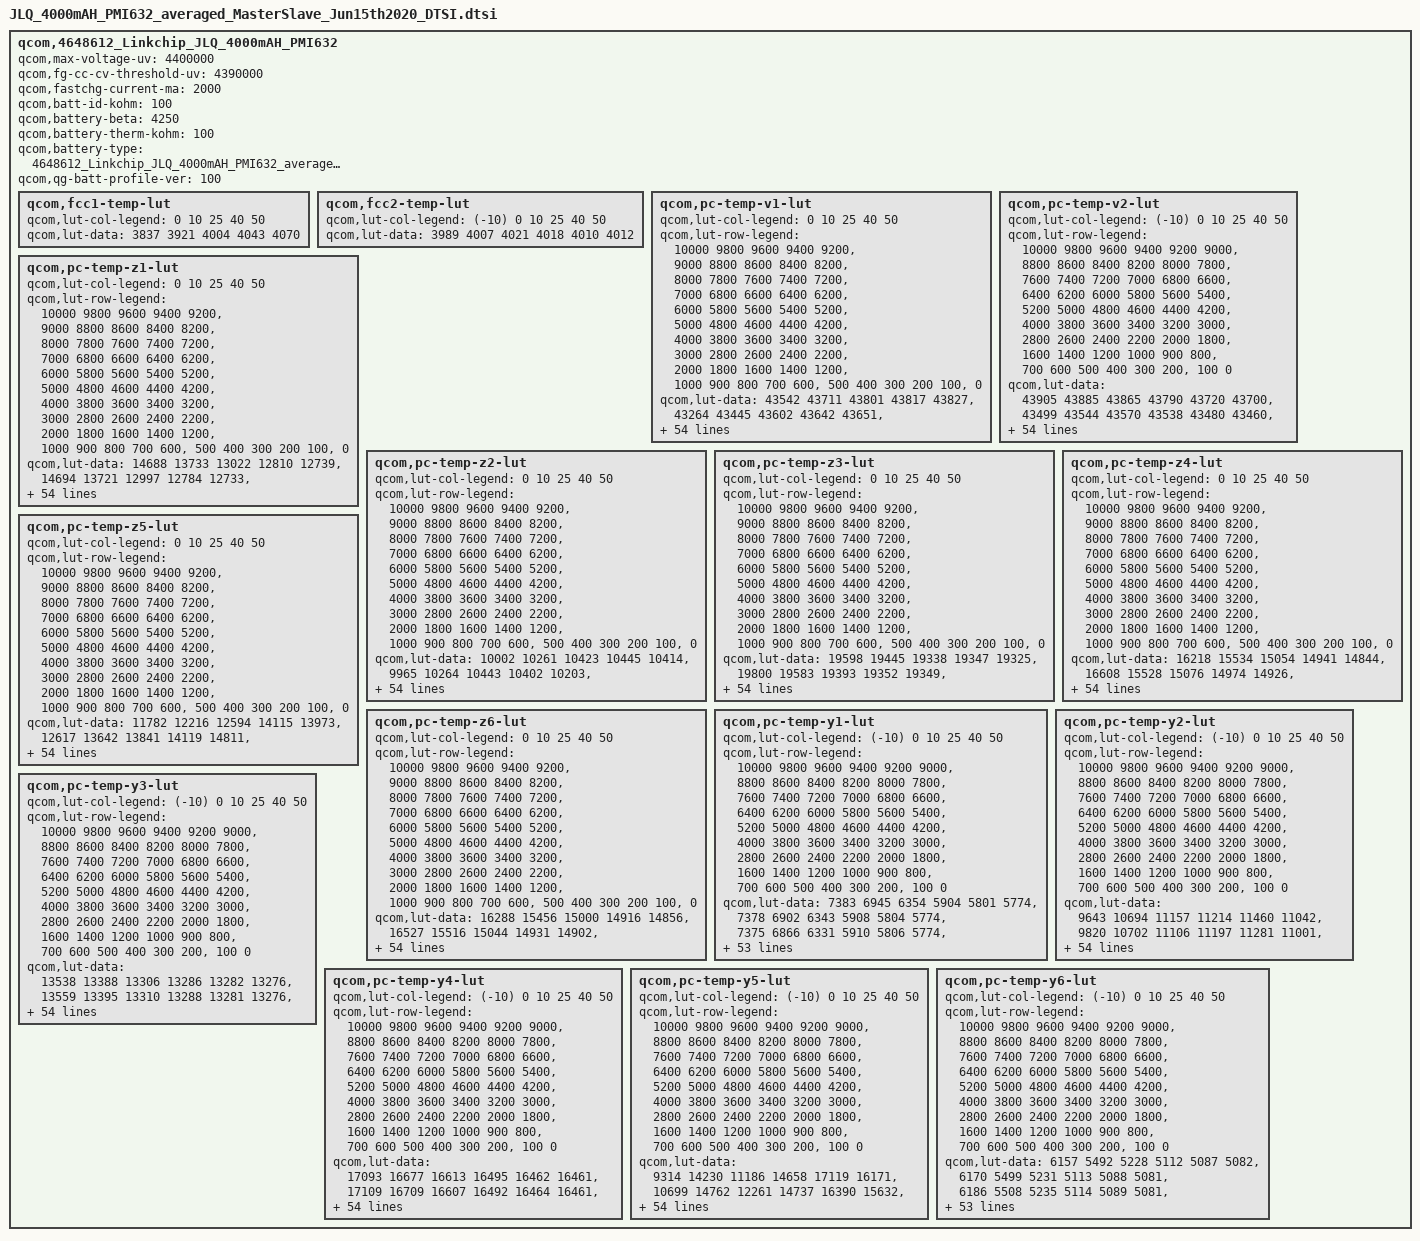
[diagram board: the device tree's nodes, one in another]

qcom,4648612_Linkchip_JLQ_4000mAH_PMI632 {
    /* 4648612_Linkchip_JLQ_4000mAH_PMI632_averaged_MasterSlave_Jun15th2020 */
    qcom,max-voltage-uv = <4400000>;
    qcom,fg-cc-cv-threshold-uv = <4390000>;
    qcom,fastchg-current-ma = <2000>;
    qcom,batt-id-kohm = <100>;
    qcom,battery-beta = <4250>;
    qcom,battery-therm-kohm = <100>;
    qcom,battery-type = "4648612_Linkchip_JLQ_4000mAH_PMI632_averaged_MasterSlave_Jun15th2020";
    qcom,qg-batt-profile-ver = <100>;

	qcom,fcc1-temp-lut {
		qcom,lut-col-legend = <0 10 25 40 50>;
		qcom,lut-data = <3837 3921 4004 4043 4070>;
	};

	qcom,fcc2-temp-lut {
		qcom,lut-col-legend = <(-10) 0 10 25 40 50>;
		qcom,lut-data = <3989 4007 4021 4018 4010 4012>;
	};

	qcom,pc-temp-v1-lut {
		qcom,lut-col-legend = <0 10 25 40 50>;
		qcom,lut-row-legend = <10000 9800 9600 9400 9200>,
			<9000 8800 8600 8400 8200>,
			<8000 7800 7600 7400 7200>,
			<7000 6800 6600 6400 6200>,
			<6000 5800 5600 5400 5200>,
			<5000 4800 4600 4400 4200>,
			<4000 3800 3600 3400 3200>,
			<3000 2800 2600 2400 2200>,
			<2000 1800 1600 1400 1200>,
			<1000 900 800 700 600>,
			<500 400 300 200 100>,
			<0>;
		qcom,lut-data = <43542 43711 43801 43817 43827>,
			<43264 43445 43602 43642 43651>,
			<43025 43195 43371 43428 43448>,
			<42799 42961 43136 43203 43229>,
			<42574 42733 42900 42970 43002>,
			<42354 42505 42663 42730 42764>,
			<42138 42278 42430 42492 42526>,
			<41925 42058 42199 42256 42289>,
			<41718 41843 41972 42023 42055>,
			<41517 41632 41748 41793 41822>,
			<41325 41428 41528 41566 41592>,
			<41130 41234 41315 41344 41367>,
			<40927 41036 41109 41127 41145>,
			<40709 40831 40906 40917 40929>,
			<40446 40607 40699 40709 40718>,
			<40099 40332 40480 40498 40510>,
			<39816 40009 40219 40283 40311>,
			<39682 39791 39957 40069 40124>,
			<39590 39687 39785 39882 39941>,
			<39496 39605 39676 39730 39767>,
			<39400 39486 39552 39575 39592>,
			<39300 39332 39323 39346 39372>,
			<39185 39162 39041 39040 39079>,
			<39056 38963 38839 38824 38849>,
			<38933 38761 38686 38708 38729>,
			<38822 38616 38569 38617 38639>,
			<38719 38501 38487 38525 38543>,
			<38626 38412 38422 38438 38447>,
			<38539 38349 38355 38357 38357>,
			<38464 38300 38286 38280 38270>,
			<38404 38255 38222 38208 38191>,
			<38351 38213 38165 38139 38117>,
			<38304 38176 38113 38074 38050>,
			<38258 38146 38063 38014 37985>,
			<38219 38119 38017 37960 37922>,
			<38191 38089 37972 37908 37861>,
			<38171 38058 37931 37859 37802>,
			<38142 38019 37889 37812 37744>,
			<38082 37957 37827 37747 37673>,
			<37990 37863 37733 37653 37581>,
			<37886 37759 37624 37544 37474>,
			<37758 37640 37508 37426 37357>,
			<37622 37507 37378 37294 37226>,
			<37478 37348 37224 37144 37078>,
			<37331 37226 37103 37023 36958>,
			<37232 37146 37033 36955 36888>,
			<37195 37126 37017 36937 36871>,
			<37168 37101 37005 36925 36857>,
			<37140 37077 36983 36902 36832>,
			<37079 37019 36909 36820 36739>,
			<36843 36752 36620 36522 36428>,
			<36399 36310 36182 36080 35983>,
			<35831 35737 35612 35505 35407>,
			<35065 34962 34834 34724 34622>,
			<33861 33746 33632 33519 33413>,
			<30000 30000 30000 30000 30000>;
	};

	qcom,pc-temp-v2-lut {
		qcom,lut-col-legend = <(-10) 0 10 25 40 50>;
		qcom,lut-row-legend = <10000 9800 9600 9400 9200 9000>,
			<8800 8600 8400 8200 8000 7800>,
			<7600 7400 7200 7000 6800 6600>,
			<6400 6200 6000 5800 5600 5400>,
			<5200 5000 4800 4600 4400 4200>,
			<4000 3800 3600 3400 3200 3000>,
			<2800 2600 2400 2200 2000 1800>,
			<1600 1400 1200 1000 900 800>,
			<700 600 500 400 300 200>,
			<100 0>;
		qcom,lut-data = <43905 43885 43865 43790 43720 43700>,
			<43499 43544 43570 43538 43480 43460>,
			<43142 43234 43292 43289 43242 43222>,
			<42841 42960 43034 43046 43003 42984>,
			<42586 42718 42795 42806 42764 42747>,
			<42351 42484 42561 42568 42526 42510>,
			<42134 42249 42326 42331 42291 42275>,
			<41924 42019 42095 42097 42057 42041>,
			<41655 41797 41871 41869 41827 41811>,
			<41279 41580 41651 41646 41600 41583>,
			<41076 41377 41437 41426 41376 41357>,
			<41129 41208 41232 41208 41155 41135>,
			<41215 41039 41027 40992 40938 40916>,
			<41103 40796 40813 40787 40729 40707>,
			<40309 40452 40590 40591 40526 40506>,
			<39632 40103 40344 40377 40323 40309>,
			<39439 39761 40035 40108 40111 40115>,
			<39313 39455 39726 39838 39900 39925>,
			<39159 39284 39522 39650 39713 39740>,
			<38981 39184 39376 39514 39545 39561>,
			<38806 39078 39223 39358 39362 39367>,
			<38640 38930 39037 39129 39128 39129>,
			<38484 38769 38853 38893 38892 38891>,
			<38358 38620 38703 38729 38725 38723>,
			<38251 38477 38574 38601 38596 38593>,
			<38166 38349 38457 38487 38482 38477>,
			<38103 38234 38349 38382 38376 38370>,
			<38052 38132 38249 38286 38278 38271>,
			<38004 38045 38158 38196 38189 38181>,
			<37962 37968 38073 38112 38107 38097>,
			<37922 37908 37995 38035 38032 38021>,
			<37881 37861 37919 37964 37961 37953>,
			<37839 37822 37852 37899 37893 37889>,
			<37793 37785 37799 37837 37824 37815>,
			<37743 37753 37757 37780 37754 37732>,
			<37689 37717 37717 37719 37679 37640>,
			<37629 37676 37683 37651 37591 37537>,
			<37565 37629 37646 37577 37500 37433>,
			<37498 37570 37593 37506 37422 37349>,
			<37428 37497 37521 37436 37353 37278>,
			<37357 37411 37437 37355 37274 37198>,
			<37287 37302 37334 37252 37171 37097>,
			<37215 37192 37215 37132 37052 36981>,
			<37135 37094 37074 36989 36913 36843>,
			<37046 37006 36972 36899 36831 36764>,
			<36936 36929 36932 36870 36803 36740>,
			<36877 36890 36909 36857 36789 36722>,
			<36808 36847 36886 36836 36769 36705>,
			<36706 36777 36846 36799 36731 36668>,
			<36538 36630 36735 36670 36595 36515>,
			<36256 36321 36399 36311 36247 36160>,
			<35793 35825 35892 35813 35754 35669>,
			<35129 35156 35247 35167 35120 35031>,
			<34152 34215 34376 34297 34267 34172>,
			<32787 32931 33105 33080 33053 32905>,
			<30302 29704 29222 29207 29339 29383>;
	};

	qcom,pc-temp-z1-lut {
		qcom,lut-col-legend = <0 10 25 40 50>;
		qcom,lut-row-legend = <10000 9800 9600 9400 9200>,
			<9000 8800 8600 8400 8200>,
			<8000 7800 7600 7400 7200>,
			<7000 6800 6600 6400 6200>,
			<6000 5800 5600 5400 5200>,
			<5000 4800 4600 4400 4200>,
			<4000 3800 3600 3400 3200>,
			<3000 2800 2600 2400 2200>,
			<2000 1800 1600 1400 1200>,
			<1000 900 800 700 600>,
			<500 400 300 200 100>,
			<0>;
		qcom,lut-data = <14688 13733 13022 12810 12739>,
			<14694 13721 12997 12784 12733>,
			<14673 13710 12974 12770 12725>,
			<14660 13693 12962 12763 12720>,
			<14657 13679 12955 12761 12716>,
			<14655 13672 12951 12761 12712>,
			<14654 13666 12951 12761 12711>,
			<14655 13665 12952 12762 12711>,
			<14657 13668 12952 12762 12710>,
			<14667 13670 12951 12760 12711>,
			<14693 13673 12951 12758 12712>,
			<14705 13677 12955 12758 12714>,
			<14680 13677 12962 12763 12719>,
			<14636 13667 12963 12767 12723>,
			<14608 13653 12957 12768 12723>,
			<14586 13642 12952 12767 12722>,
			<14568 13631 12949 12768 12722>,
			<14556 13627 12946 12770 12724>,
			<14547 13641 12947 12773 12727>,
			<14543 13660 12954 12774 12728>,
			<14546 13670 12962 12776 12730>,
			<14550 13678 12969 12778 12732>,
			<14543 13684 12977 12780 12735>,
			<14526 13683 12979 12782 12737>,
			<14517 13681 12980 12784 12741>,
			<14518 13685 12981 12785 12745>,
			<14520 13697 12984 12787 12748>,
			<14520 13707 12988 12790 12751>,
			<14515 13712 12992 12792 12753>,
			<14509 13715 12995 12795 12756>,
			<14508 13721 12998 12798 12759>,
			<14508 13729 13003 12803 12760>,
			<14507 13735 13007 12808 12761>,
			<14487 13732 13010 12811 12762>,
			<14466 13724 13013 12814 12765>,
			<14465 13725 13015 12816 12769>,
			<14471 13741 13019 12818 12770>,
			<14481 13757 13023 12820 12772>,
			<14524 13756 13026 12822 12773>,
			<14581 13746 13029 12825 12775>,
			<14584 13741 13031 12826 12778>,
			<14519 13741 13031 12827 12777>,
			<14503 13741 13031 12827 12775>,
			<14571 13747 13031 12826 12775>,
			<14563 13737 13036 12826 12778>,
			<14507 13739 13038 12827 12777>,
			<14534 13743 13026 12826 12777>,
			<14505 13723 13032 12825 12779>,
			<14443 13732 13034 12828 12781>,
			<14520 13732 13041 12827 12776>,
			<14519 13757 13039 12829 12778>,
			<14545 13779 13050 12835 12782>,
			<14515 13767 13064 12843 12789>,
			<14526 13804 13088 12853 12804>,
			<14526 13804 13088 12853 12804>,
			<14526 13804 13088 12853 12804>;
	};

	qcom,pc-temp-z2-lut {
		qcom,lut-col-legend = <0 10 25 40 50>;
		qcom,lut-row-legend = <10000 9800 9600 9400 9200>,
			<9000 8800 8600 8400 8200>,
			<8000 7800 7600 7400 7200>,
			<7000 6800 6600 6400 6200>,
			<6000 5800 5600 5400 5200>,
			<5000 4800 4600 4400 4200>,
			<4000 3800 3600 3400 3200>,
			<3000 2800 2600 2400 2200>,
			<2000 1800 1600 1400 1200>,
			<1000 900 800 700 600>,
			<500 400 300 200 100>,
			<0>;
		qcom,lut-data = <10002 10261 10423 10445 10414>,
			<9965 10264 10443 10402 10203>,
			<9998 10261 10488 10480 10263>,
			<10035 10239 10491 10516 10360>,
			<10063 10213 10458 10498 10402>,
			<10091 10197 10423 10472 10426>,
			<10098 10183 10397 10460 10426>,
			<10088 10176 10376 10443 10408>,
			<10074 10172 10367 10424 10381>,
			<10067 10170 10364 10389 10316>,
			<10062 10166 10362 10353 10212>,
			<10054 10160 10356 10337 10165>,
			<10027 10151 10348 10304 10138>,
			<9990 10137 10347 10276 10124>,
			<9962 10120 10362 10329 10162>,
			<9934 10102 10375 10429 10258>,
			<9916 10083 10362 10414 10296>,
			<9918 10076 10336 10265 10257>,
			<9926 10120 10339 10183 10224>,
			<9935 10191 10413 10248 10263>,
			<9950 10232 10496 10363 10330>,
			<9968 10259 10555 10484 10375>,
			<9986 10287 10603 10630 10426>,
			<10004 10330 10617 10684 10456>,
			<10018 10374 10622 10551 10428>,
			<10026 10382 10624 10397 10378>,
			<10034 10378 10607 10385 10385>,
			<10044 10371 10578 10394 10460>,
			<10058 10361 10577 10405 10505>,
			<10073 10348 10609 10424 10510>,
			<10088 10344 10630 10455 10513>,
			<10106 10344 10628 10533 10492>,
			<10125 10345 10624 10661 10419>,
			<10153 10347 10623 10701 10381>,
			<10175 10350 10624 10672 10379>,
			<10141 10354 10625 10646 10388>,
			<9992 10360 10633 10657 10421>,
			<9897 10368 10650 10690 10495>,
			<9960 10380 10672 10722 10570>,
			<10070 10396 10704 10782 10660>,
			<10115 10403 10726 10822 10719>,
			<10136 10401 10730 10854 10706>,
			<10107 10400 10732 10895 10673>,
			<9839 10414 10729 10745 10660>,
			<9840 10552 10760 10676 10648>,
			<9788 10607 10758 10678 10633>,
			<9777 10607 10657 10651 10622>,
			<9765 10614 10625 10672 10631>,
			<9763 10686 10665 10690 10687>,
			<9757 10709 10698 10852 10820>,
			<9738 10586 10858 10906 10506>,
			<9720 10466 10802 10621 10244>,
			<9668 10370 10850 10465 10166>,
			<9586 10239 10706 10349 10087>,
			<9586 10239 10706 10349 10087>,
			<9586 10239 10706 10349 10087>;
	};

	qcom,pc-temp-z3-lut {
		qcom,lut-col-legend = <0 10 25 40 50>;
		qcom,lut-row-legend = <10000 9800 9600 9400 9200>,
			<9000 8800 8600 8400 8200>,
			<8000 7800 7600 7400 7200>,
			<7000 6800 6600 6400 6200>,
			<6000 5800 5600 5400 5200>,
			<5000 4800 4600 4400 4200>,
			<4000 3800 3600 3400 3200>,
			<3000 2800 2600 2400 2200>,
			<2000 1800 1600 1400 1200>,
			<1000 900 800 700 600>,
			<500 400 300 200 100>,
			<0>;
		qcom,lut-data = <19598 19445 19338 19347 19325>,
			<19800 19583 19393 19352 19349>,
			<19853 19633 19457 19390 19372>,
			<19873 19648 19482 19415 19390>,
			<19858 19654 19490 19428 19403>,
			<19822 19655 19493 19437 19414>,
			<19797 19655 19490 19441 19419>,
			<19776 19654 19483 19442 19420>,
			<19761 19645 19480 19441 19420>,
			<19763 19635 19480 19437 19418>,
			<19773 19633 19479 19431 19410>,
			<19784 19631 19475 19426 19402>,
			<19807 19630 19468 19414 19391>,
			<19839 19628 19461 19404 19380>,
			<19852 19631 19453 19402 19375>,
			<19866 19636 19449 19401 19372>,
			<19874 19638 19448 19393 19371>,
			<19847 19626 19440 19372 19360>,
			<19787 19585 19429 19360 19350>,
			<19742 19542 19413 19360 19350>,
			<19710 19538 19403 19362 19352>,
			<19688 19553 19421 19370 19354>,
			<19698 19571 19455 19388 19359>,
			<19753 19593 19462 19396 19363>,
			<19782 19613 19458 19386 19353>,
			<19779 19617 19452 19372 19335>,
			<19776 19614 19441 19362 19328>,
			<19775 19609 19427 19353 19323>,
			<19772 19603 19422 19350 19322>,
			<19769 19594 19420 19352 19334>,
			<19767 19588 19419 19354 19350>,
			<19768 19583 19421 19364 19357>,
			<19771 19579 19423 19382 19364>,
			<19782 19573 19424 19388 19367>,
			<19791 19568 19426 19384 19362>,
			<19762 19563 19427 19378 19356>,
			<19654 19558 19424 19372 19352>,
			<19581 19553 19419 19365 19349>,
			<19612 19551 19415 19360 19345>,
			<19670 19548 19411 19356 19340>,
			<19679 19544 19408 19353 19337>,
			<19658 19536 19406 19355 19339>,
			<19603 19526 19403 19360 19342>,
			<19432 19516 19399 19355 19341>,
			<19370 19467 19385 19346 19335>,
			<19340 19426 19376 19337 19329>,
			<19338 19332 19367 19336 19322>,
			<19337 19320 19344 19326 19317>,
			<19334 19311 19340 19323 19311>,
			<19331 19310 19336 19317 19312>,
			<19338 19334 19327 19309 19340>,
			<19351 19330 19324 19322 19346>,
			<19365 19333 19320 19331 19348>,
			<19376 19325 19320 19335 19344>,
			<19376 19325 19320 19335 19344>,
			<19376 19325 19320 19335 19344>;
	};

	qcom,pc-temp-z4-lut {
		qcom,lut-col-legend = <0 10 25 40 50>;
		qcom,lut-row-legend = <10000 9800 9600 9400 9200>,
			<9000 8800 8600 8400 8200>,
			<8000 7800 7600 7400 7200>,
			<7000 6800 6600 6400 6200>,
			<6000 5800 5600 5400 5200>,
			<5000 4800 4600 4400 4200>,
			<4000 3800 3600 3400 3200>,
			<3000 2800 2600 2400 2200>,
			<2000 1800 1600 1400 1200>,
			<1000 900 800 700 600>,
			<500 400 300 200 100>,
			<0>;
		qcom,lut-data = <16218 15534 15054 14941 14844>,
			<16608 15528 15076 14974 14926>,
			<16439 15489 15072 14971 14921>,
			<16243 15379 15057 14960 14909>,
			<16111 15262 15005 14932 14890>,
			<15994 15186 14951 14892 14858>,
			<15891 15122 14918 14860 14829>,
			<15801 15071 14891 14832 14804>,
			<15718 15032 14863 14808 14782>,
			<15634 14999 14833 14787 14765>,
			<15552 14970 14809 14767 14750>,
			<15475 14943 14795 14757 14739>,
			<15391 14917 14783 14752 14733>,
			<15319 14888 14770 14746 14727>,
			<15288 14862 14753 14731 14718>,
			<15272 14847 14741 14711 14704>,
			<15257 14837 14739 14709 14695>,
			<15223 14826 14737 14713 14687>,
			<15171 14812 14734 14714 14683>,
			<15136 14800 14726 14709 14684>,
			<15116 14792 14720 14703 14687>,
			<15099 14779 14755 14732 14708>,
			<15066 14772 14820 14829 14804>,
			<14996 14797 14853 14875 14868>,
			<14960 14835 14873 14874 14868>,
			<14961 14850 14882 14872 14865>,
			<14963 14860 14875 14868 14861>,
			<14963 14866 14857 14858 14850>,
			<14957 14860 14840 14845 14834>,
			<14949 14844 14822 14825 14803>,
			<14938 14831 14804 14800 14766>,
			<14922 14819 14783 14767 14738>,
			<14903 14807 14763 14730 14711>,
			<14871 14795 14749 14716 14700>,
			<14842 14783 14737 14713 14701>,
			<14857 14773 14730 14712 14703>,
			<14941 14762 14728 14713 14706>,
			<14994 14753 14726 14717 14710>,
			<14930 14750 14729 14724 14717>,
			<14826 14747 14742 14741 14733>,
			<14798 14744 14751 14753 14745>,
			<14800 14737 14746 14748 14742>,
			<14824 14729 14739 14739 14735>,
			<14989 14721 14738 14745 14739>,
			<14944 14708 14719 14734 14733>,
			<14943 14714 14686 14702 14701>,
			<14940 14811 14678 14685 14690>,
			<14935 14816 14682 14670 14668>,
			<14932 14820 14672 14650 14645>,
			<14930 14817 14680 14661 14649>,
			<14926 14805 14725 14716 14665>,
			<14935 14824 14739 14709 14666>,
			<14941 14832 14749 14701 14665>,
			<14957 14857 14755 14698 14671>,
			<14957 14857 14755 14698 14671>,
			<14957 14857 14755 14698 14671>;
	};

	qcom,pc-temp-z5-lut {
		qcom,lut-col-legend = <0 10 25 40 50>;
		qcom,lut-row-legend = <10000 9800 9600 9400 9200>,
			<9000 8800 8600 8400 8200>,
			<8000 7800 7600 7400 7200>,
			<7000 6800 6600 6400 6200>,
			<6000 5800 5600 5400 5200>,
			<5000 4800 4600 4400 4200>,
			<4000 3800 3600 3400 3200>,
			<3000 2800 2600 2400 2200>,
			<2000 1800 1600 1400 1200>,
			<1000 900 800 700 600>,
			<500 400 300 200 100>,
			<0>;
		qcom,lut-data = <11782 12216 12594 14115 13973>,
			<12617 13642 13841 14119 14811>,
			<12952 14285 15321 15342 15772>,
			<13129 14550 15943 16179 16596>,
			<13226 14749 16203 16672 17385>,
			<13295 14999 16347 17114 18129>,
			<13360 15270 16327 17506 18732>,
			<13424 15445 16239 17878 19288>,
			<13504 15566 16303 18085 19694>,
			<13639 15707 16823 18297 19782>,
			<13852 15964 17348 18591 19718>,
			<14106 16401 17622 18709 19695>,
			<14690 16780 17839 18389 19193>,
			<15425 18001 18224 18241 18627>,
			<15637 19484 19699 20062 19502>,
			<15634 19851 20995 22897 22264>,
			<15617 19645 20751 22670 23243>,
			<15552 19005 19758 19136 21416>,
			<15408 18348 19648 17134 19903>,
			<15300 17851 20148 18352 21077>,
			<15215 18789 21125 20898 23291>,
			<15169 23755 30221 25468 25380>,
			<16204 29966 45281 33382 27917>,
			<19781 38517 48197 36616 29307>,
			<22665 47202 42388 31077 25665>,
			<24014 48434 35567 23622 19479>,
			<25019 45086 29967 20186 16845>,
			<25941 41250 25014 17924 15438>,
			<27008 37701 22820 17013 14937>,
			<27748 34066 21636 16693 15456>,
			<27838 32263 21134 16531 16406>,
			<27691 31303 21575 17909 17765>,
			<27733 30684 22572 21649 20349>,
			<29213 30355 23928 24191 22527>,
			<30623 30102 26539 25935 24275>,
			<28668 29982 28343 26957 25467>,
			<22411 30330 28686 26669 25567>,
			<18490 30927 28812 25734 25372>,
			<19938 32055 28569 24609 24851>,
			<22545 34182 27668 22558 21925>,
			<22998 35036 26741 20936 19222>,
			<21857 32885 26103 20926 19001>,
			<19290 30958 25494 21131 18948>,
			<12803 30451 24398 19829 18202>,
			<12413 25674 24813 19645 17769>,
			<12030 20022 25913 19795 18011>,
			<11986 12823 23106 20269 17370>,
			<11948 12474 17838 19411 18071>,
			<11910 12256 17625 21348 21246>,
			<11883 12287 17363 18785 20135>,
			<12041 13063 15058 14085 18202>,
			<12134 12722 13960 14259 17771>,
			<12172 12610 13315 14453 17539>,
			<12082 12189 12966 14405 16233>,
			<12082 12189 12966 14405 16233>,
			<12082 12189 12966 14405 16233>;
	};

	qcom,pc-temp-z6-lut {
		qcom,lut-col-legend = <0 10 25 40 50>;
		qcom,lut-row-legend = <10000 9800 9600 9400 9200>,
			<9000 8800 8600 8400 8200>,
			<8000 7800 7600 7400 7200>,
			<7000 6800 6600 6400 6200>,
			<6000 5800 5600 5400 5200>,
			<5000 4800 4600 4400 4200>,
			<4000 3800 3600 3400 3200>,
			<3000 2800 2600 2400 2200>,
			<2000 1800 1600 1400 1200>,
			<1000 900 800 700 600>,
			<500 400 300 200 100>,
			<0>;
		qcom,lut-data = <16288 15456 15000 14916 14856>,
			<16527 15516 15044 14931 14902>,
			<16476 15521 15067 14948 14911>,
			<16408 15479 15068 14956 14914>,
			<16341 15428 15050 14951 14913>,
			<16269 15395 15028 14940 14906>,
			<16207 15366 15011 14929 14897>,
			<16156 15341 14996 14918 14888>,
			<16113 15318 14983 14907 14879>,
			<16077 15298 14971 14896 14869>,
			<16046 15284 14960 14884 14860>,
			<16018 15272 14952 14876 14851>,
			<15989 15259 14944 14869 14842>,
			<15965 15242 14935 14862 14834>,
			<15954 15228 14922 14852 14826>,
			<15947 15223 14913 14844 14819>,
			<15936 15216 14910 14838 14813>,
			<15904 15206 14905 14830 14804>,
			<15849 15180 14899 14824 14798>,
			<15810 15154 14888 14821 14798>,
			<15783 15151 14881 14819 14800>,
			<15766 15156 14906 14834 14809>,
			<15760 15164 14951 14886 14854>,
			<15756 15187 14969 14911 14884>,
			<15755 15216 14976 14906 14879>,
			<15757 15226 14978 14897 14870>,
			<15760 15231 14971 14890 14863>,
			<15760 15233 14957 14883 14857>,
			<15755 15228 14946 14875 14851>,
			<15748 15217 14938 14867 14844>,
			<15743 15209 14931 14859 14837>,
			<15738 15203 14924 14853 14830>,
			<15733 15197 14917 14847 14823>,
			<15729 15190 14912 14843 14818>,
			<15725 15184 14909 14839 14815>,
			<15717 15178 14906 14837 14814>,
			<15703 15172 14902 14834 14813>,
			<15694 15168 14900 14832 14813>,
			<15689 15167 14900 14832 14813>,
			<15684 15167 14904 14837 14817>,
			<15678 15166 14907 14841 14821>,
			<15666 15160 14904 14840 14820>,
			<15649 15152 14899 14838 14819>,
			<15624 15146 14896 14837 14819>,
			<15563 15116 14882 14828 14815>,
			<15542 15098 14863 14810 14797>,
			<15539 15091 14854 14802 14789>,
			<15536 15088 14845 14790 14777>,
			<15535 15086 14838 14779 14763>,
			<15537 15087 14841 14780 14764>,
			<15547 15098 14857 14801 14788>,
			<15564 15110 14864 14807 14794>,
			<15588 15124 14869 14811 14797>,
			<15617 15144 14878 14816 14802>,
			<15617 15144 14878 14816 14802>,
			<15617 15144 14878 14816 14802>;
	};

	qcom,pc-temp-y1-lut {
		qcom,lut-col-legend = <(-10) 0 10 25 40 50>;
		qcom,lut-row-legend = <10000 9800 9600 9400 9200 9000>,
			<8800 8600 8400 8200 8000 7800>,
			<7600 7400 7200 7000 6800 6600>,
			<6400 6200 6000 5800 5600 5400>,
			<5200 5000 4800 4600 4400 4200>,
			<4000 3800 3600 3400 3200 3000>,
			<2800 2600 2400 2200 2000 1800>,
			<1600 1400 1200 1000 900 800>,
			<700 600 500 400 300 200>,
			<100 0>;
		qcom,lut-data = <7383 6945 6354 5904 5801 5774>,
			<7378 6902 6343 5908 5804 5774>,
			<7375 6866 6331 5910 5806 5774>,
			<7372 6838 6320 5911 5807 5773>,
			<7371 6820 6311 5911 5808 5772>,
			<7369 6812 6304 5911 5808 5772>,
			<7384 6819 6299 5908 5808 5771>,
			<7410 6832 6295 5903 5808 5770>,
			<7415 6834 6295 5901 5807 5769>,
			<7412 6830 6302 5900 5805 5769>,
			<7408 6827 6306 5899 5804 5769>,
			<7389 6825 6299 5900 5805 5768>,
			<7359 6822 6290 5901 5805 5767>,
			<7352 6821 6287 5902 5805 5766>,
			<7355 6815 6286 5902 5805 5765>,
			<7357 6808 6287 5902 5805 5765>,
			<7371 6804 6295 5906 5806 5765>,
			<7394 6800 6306 5909 5806 5764>,
			<7394 6798 6307 5910 5806 5765>,
			<7345 6797 6300 5910 5806 5766>,
			<7306 6796 6295 5911 5805 5768>,
			<7314 6801 6300 5911 5806 5769>,
			<7338 6808 6308 5912 5807 5769>,
			<7361 6809 6309 5914 5808 5771>,
			<7387 6804 6304 5920 5809 5773>,
			<7402 6798 6301 5925 5810 5774>,
			<7400 6786 6304 5925 5813 5775>,
			<7395 6771 6309 5926 5817 5777>,
			<7388 6772 6310 5927 5820 5778>,
			<7371 6804 6310 5930 5822 5780>,
			<7348 6827 6311 5933 5824 5781>,
			<7316 6818 6316 5936 5826 5783>,
			<7278 6799 6323 5939 5828 5786>,
			<7270 6793 6324 5941 5830 5788>,
			<7322 6790 6317 5942 5831 5790>,
			<7371 6789 6310 5943 5833 5792>,
			<7358 6791 6306 5943 5836 5793>,
			<7321 6795 6303 5942 5838 5793>,
			<7305 6803 6304 5943 5838 5794>,
			<7302 6817 6311 5946 5836 5795>,
			<7300 6827 6319 5948 5835 5796>,
			<7281 6812 6329 5945 5836 5797>,
			<7247 6792 6335 5942 5837 5797>,
			<7242 6789 6320 5941 5837 5799>,
			<7248 6791 6325 5944 5838 5800>,
			<7302 6790 6343 5947 5837 5799>,
			<7297 6796 6332 5950 5838 5799>,
			<7280 6826 6330 5951 5840 5801>,
			<7256 6837 6333 5951 5841 5801>,
			<7241 6812 6344 5953 5840 5802>,
			<7227 6838 6340 5955 5841 5806>,
			<7301 6847 6355 5964 5846 5811>,
			<7336 6827 6379 5973 5855 5815>,
			<7369 6867 6410 5985 5865 5823>,
			<7369 6867 6410 5985 5865 5823>,
			<7369 6867 6410 5985 5865 5823>;
	};

	qcom,pc-temp-y2-lut {
		qcom,lut-col-legend = <(-10) 0 10 25 40 50>;
		qcom,lut-row-legend = <10000 9800 9600 9400 9200 9000>,
			<8800 8600 8400 8200 8000 7800>,
			<7600 7400 7200 7000 6800 6600>,
			<6400 6200 6000 5800 5600 5400>,
			<5200 5000 4800 4600 4400 4200>,
			<4000 3800 3600 3400 3200 3000>,
			<2800 2600 2400 2200 2000 1800>,
			<1600 1400 1200 1000 900 800>,
			<700 600 500 400 300 200>,
			<100 0>;
		qcom,lut-data = <9643 10694 11157 11214 11460 11042>,
			<9820 10702 11106 11197 11281 11001>,
			<10046 10704 11055 11170 11116 10961>,
			<10192 10700 11007 11143 10979 10923>,
			<10270 10693 10966 11121 10885 10889>,
			<10294 10683 10936 11114 10851 10860>,
			<10214 10667 10915 11118 10889 10830>,
			<10088 10649 10900 11123 10951 10806>,
			<10132 10636 10887 11110 10961 10805>,
			<10523 10627 10877 11057 10942 10815>,
			<10789 10615 10864 11026 10929 10821>,
			<10560 10576 10836 11041 10945 10809>,
			<10181 10531 10809 11062 10966 10790>,
			<10133 10565 10816 11052 10967 10788>,
			<10338 10763 10865 10997 10948 10813>,
			<10490 10885 10910 10967 10937 10842>,
			<10507 10863 10934 11094 11045 10900>,
			<10515 10830 10957 11276 11230 10991>,
			<10492 10829 10991 11321 11351 11116>,
			<10297 10848 11038 11331 11450 11332>,
			<10128 10861 11072 11330 11489 11442>,
			<9968 10864 11087 11302 11436 11320>,
			<9752 10866 11099 11271 11369 11152>,
			<9703 10865 11113 11275 11362 11134>,
			<9693 10862 11128 11312 11373 11171>,
			<9687 10859 11140 11358 11382 11214>,
			<9681 10859 11148 11423 11386 11267>,
			<9677 10858 11152 11478 11394 11332>,
			<9674 10856 11147 11482 11430 11387>,
			<9673 10841 11127 11470 11506 11440>,
			<9671 10824 11117 11458 11536 11518>,
			<9669 10804 11116 11433 11605 11728>,
			<9667 10776 11115 11401 11716 11950>,
			<9665 10740 11110 11381 11706 11971>,
			<9663 10677 11090 11355 11564 11859>,
			<9661 10606 11069 11339 11434 11750>,
			<9659 10539 11050 11334 11344 11589>,
			<9659 10467 11028 11332 11283 11429>,
			<9658 10366 10998 11323 11278 11359>,
			<9658 10191 10954 11299 11290 11294>,
			<9658 10015 10903 11282 11299 11266>,
			<9658 9825 10847 11284 11276 11278>,
			<9658 9724 10776 11272 11244 11286>,
			<9658 9697 10679 11208 11291 11230>,
			<9657 9684 10574 11171 11222 11046>,
			<9657 9692 10645 11208 11046 10962>,
			<9657 9686 10629 11173 11091 10924>,
			<9657 9679 10610 11219 11136 10990>,
			<9657 9673 10582 11203 11169 11046>,
			<9657 9668 10561 11219 11161 10991>,
			<9656 9663 10504 11156 11046 10851>,
			<9656 9659 10386 11083 10900 10771>,
			<9655 9657 10290 10987 10886 10656>,
			<9653 9655 10215 10849 10798 10567>,
			<9653 9655 10215 10849 10798 10567>,
			<9653 9655 10215 10849 10798 10567>;
	};

	qcom,pc-temp-y3-lut {
		qcom,lut-col-legend = <(-10) 0 10 25 40 50>;
		qcom,lut-row-legend = <10000 9800 9600 9400 9200 9000>,
			<8800 8600 8400 8200 8000 7800>,
			<7600 7400 7200 7000 6800 6600>,
			<6400 6200 6000 5800 5600 5400>,
			<5200 5000 4800 4600 4400 4200>,
			<4000 3800 3600 3400 3200 3000>,
			<2800 2600 2400 2200 2000 1800>,
			<1600 1400 1200 1000 900 800>,
			<700 600 500 400 300 200>,
			<100 0>;
		qcom,lut-data = <13538 13388 13306 13286 13282 13276>,
			<13559 13395 13310 13288 13281 13276>,
			<13581 13401 13317 13290 13282 13276>,
			<13601 13408 13325 13292 13282 13277>,
			<13618 13413 13331 13294 13283 13278>,
			<13631 13417 13334 13295 13285 13279>,
			<13642 13422 13334 13296 13287 13281>,
			<13649 13425 13335 13296 13290 13283>,
			<13649 13424 13336 13298 13291 13285>,
			<13637 13421 13340 13303 13292 13288>,
			<13617 13419 13343 13306 13292 13289>,
			<13545 13447 13345 13305 13293 13289>,
			<13448 13488 13347 13304 13295 13290>,
			<13435 13487 13351 13304 13296 13290>,
			<13481 13448 13362 13308 13297 13291>,
			<13513 13411 13368 13310 13298 13292>,
			<13506 13388 13359 13307 13298 13292>,
			<13491 13371 13347 13303 13299 13291>,
			<13480 13371 13343 13303 13299 13291>,
			<13469 13383 13341 13306 13297 13293>,
			<13461 13389 13338 13308 13295 13294>,
			<13460 13387 13329 13299 13289 13287>,
			<13460 13384 13320 13288 13283 13279>,
			<13460 13379 13319 13285 13281 13278>,
			<13459 13371 13320 13285 13280 13278>,
			<13460 13363 13320 13284 13280 13278>,
			<13467 13357 13320 13286 13279 13278>,
			<13480 13352 13320 13289 13278 13277>,
			<13493 13347 13320 13290 13278 13277>,
			<13508 13341 13321 13291 13279 13277>,
			<13528 13338 13321 13292 13280 13277>,
			<13560 13338 13320 13292 13281 13277>,
			<13604 13338 13320 13292 13281 13279>,
			<13654 13340 13320 13292 13281 13279>,
			<13718 13353 13321 13293 13281 13278>,
			<13789 13367 13322 13293 13280 13278>,
			<13867 13378 13325 13293 13280 13276>,
			<13948 13391 13328 13292 13279 13274>,
			<14014 13404 13330 13292 13279 13274>,
			<14068 13417 13331 13292 13279 13275>,
			<14113 13433 13332 13292 13280 13276>,
			<14152 13454 13334 13292 13279 13277>,
			<14188 13485 13336 13292 13279 13277>,
			<14224 13530 13333 13288 13279 13276>,
			<14268 13576 13333 13287 13282 13277>,
			<14217 13547 13338 13292 13284 13284>,
			<14197 13569 13339 13296 13288 13285>,
			<14219 13610 13347 13301 13292 13291>,
			<14304 13660 13357 13309 13299 13295>,
			<14390 13724 13365 13309 13297 13290>,
			<14498 13818 13363 13298 13289 13287>,
			<14644 14012 13380 13304 13289 13288>,
			<15057 14264 13411 13313 13296 13291>,
			<16057 14676 13457 13323 13305 13298>,
			<16057 14676 13457 13323 13305 13298>,
			<16057 14676 13457 13323 13305 13298>;
	};

	qcom,pc-temp-y4-lut {
		qcom,lut-col-legend = <(-10) 0 10 25 40 50>;
		qcom,lut-row-legend = <10000 9800 9600 9400 9200 9000>,
			<8800 8600 8400 8200 8000 7800>,
			<7600 7400 7200 7000 6800 6600>,
			<6400 6200 6000 5800 5600 5400>,
			<5200 5000 4800 4600 4400 4200>,
			<4000 3800 3600 3400 3200 3000>,
			<2800 2600 2400 2200 2000 1800>,
			<1600 1400 1200 1000 900 800>,
			<700 600 500 400 300 200>,
			<100 0>;
		qcom,lut-data = <17093 16677 16613 16495 16462 16461>,
			<17109 16709 16607 16492 16464 16461>,
			<17131 16747 16603 16492 16467 16462>,
			<17158 16784 16601 16493 16469 16463>,
			<17189 16814 16601 16495 16471 16464>,
			<17224 16833 16601 16498 16473 16464>,
			<17275 16841 16605 16504 16474 16465>,
			<17323 16847 16614 16511 16475 16467>,
			<17327 16858 16624 16515 16479 16468>,
			<17297 16878 16637 16518 16487 16471>,
			<17276 16899 16644 16522 16496 16475>,
			<17725 16915 16644 16532 16502 16482>,
			<18456 16932 16643 16548 16509 16491>,
			<18447 16954 16661 16566 16518 16501>,
			<17485 16985 16739 16589 16533 16511>,
			<16819 17001 16783 16611 16550 16521>,
			<16841 16885 16756 16634 16571 16536>,
			<16887 16715 16713 16653 16593 16552>,
			<16902 16693 16687 16657 16605 16564>,
			<16898 16732 16668 16646 16615 16578>,
			<16894 16754 16645 16628 16613 16583>,
			<16886 16729 16607 16571 16558 16541>,
			<16867 16686 16571 16509 16488 16484>,
			<16858 16659 16557 16502 16477 16472>,
			<16854 16640 16549 16502 16477 16470>,
			<16852 16628 16546 16503 16480 16470>,
			<16854 16621 16545 16506 16489 16476>,
			<16858 16617 16545 16510 16502 16488>,
			<16861 16617 16545 16516 16515 16500>,
			<16866 16620 16545 16526 16528 16514>,
			<16869 16624 16544 16536 16540 16527>,
			<16870 16633 16540 16550 16551 16542>,
			<16874 16644 16535 16561 16559 16554>,
			<16881 16649 16535 16564 16559 16554>,
			<16898 16650 16538 16565 16555 16544>,
			<16915 16652 16543 16564 16547 16531>,
			<16929 16666 16553 16542 16522 16508>,
			<16943 16689 16564 16516 16494 16488>,
			<16958 16714 16569 16513 16492 16487>,
			<16974 16748 16573 16513 16498 16490>,
			<16992 16777 16576 16513 16501 16492>,
			<17012 16797 16581 16514 16502 16492>,
			<17036 16810 16585 16513 16501 16489>,
			<17073 16820 16587 16498 16482 16472>,
			<17092 16844 16596 16495 16473 16467>,
			<17024 16823 16580 16509 16493 16480>,
			<17014 16853 16605 16526 16508 16499>,
			<17039 16905 16642 16547 16527 16523>,
			<17067 16960 16689 16574 16556 16554>,
			<17098 16991 16716 16573 16540 16525>,
			<17100 16977 16668 16518 16492 16477>,
			<17091 16987 16673 16514 16492 16476>,
			<17300 17048 16732 16533 16498 16483>,
			<18208 17353 16841 16613 16545 16521>,
			<18208 17353 16841 16613 16545 16521>,
			<18208 17353 16841 16613 16545 16521>;
	};

	qcom,pc-temp-y5-lut {
		qcom,lut-col-legend = <(-10) 0 10 25 40 50>;
		qcom,lut-row-legend = <10000 9800 9600 9400 9200 9000>,
			<8800 8600 8400 8200 8000 7800>,
			<7600 7400 7200 7000 6800 6600>,
			<6400 6200 6000 5800 5600 5400>,
			<5200 5000 4800 4600 4400 4200>,
			<4000 3800 3600 3400 3200 3000>,
			<2800 2600 2400 2200 2000 1800>,
			<1600 1400 1200 1000 900 800>,
			<700 600 500 400 300 200>,
			<100 0>;
		qcom,lut-data = <9314 14230 11186 14658 17119 16171>,
			<10699 14762 12261 14737 16390 15632>,
			<12174 15127 13154 14725 15899 15304>,
			<13583 15353 13830 14640 15584 15136>,
			<14772 15468 14257 14502 15386 15073>,
			<15584 15498 14400 14330 15244 15064>,
			<16126 15322 14169 14011 15480 15309>,
			<16494 15053 13787 13680 15863 15711>,
			<16058 15087 13616 13722 15677 15861>,
			<13299 15514 13571 14164 15023 16060>,
			<11434 15780 13595 14422 14499 15998>,
			<12256 15031 13629 14006 14298 15413>,
			<14081 13920 13678 13372 14237 14684>,
			<16094 14342 13883 13137 14170 14296>,
			<18844 17293 14610 13016 13730 14011>,
			<20387 19088 15626 12973 13428 13913>,
			<19443 17437 17881 13216 13410 13659>,
			<17710 15038 20221 13782 13429 13268>,
			<16770 15126 20380 15066 13831 13516>,
			<15990 17470 19579 17883 15441 14979>,
			<15381 19151 18628 19261 16657 16129>,
			<14324 19571 17322 17493 17075 16630>,
			<12868 19809 16217 15182 17329 16978>,
			<12189 19561 16261 14713 17156 16927>,
			<11765 18084 16779 14585 16479 16737>,
			<11564 16665 17135 14561 15812 16451>,
			<11533 15900 17280 15281 15189 15720>,
			<11514 15252 17419 16325 14700 14890>,
			<11506 14531 17692 16869 14724 14602>,
			<11543 13621 18091 17257 15053 14465>,
			<11604 13127 18314 17551 15459 14430>,
			<11756 12904 18356 17803 15939 14765>,
			<11953 12756 18372 18084 16470 15373>,
			<12007 12903 18390 18653 17020 16021>,
			<12022 13749 18347 19956 17714 16771>,
			<12029 14454 18410 20606 18052 17052>,
			<11994 14742 19017 20380 17960 16978>,
			<11953 14969 19678 19935 17802 16824>,
			<11948 15022 19461 19314 17552 16493>,
			<11899 14656 18422 18410 16927 15900>,
			<11850 14181 17497 17659 16262 15608>,
			<11917 13105 16943 17148 15626 15618>,
			<12058 12534 16260 16671 15343 15783>,
			<12162 12420 14748 15984 16292 16286>,
			<12383 12315 13732 14690 16427 15328>,
			<12521 12541 15370 14988 14660 15573>,
			<12608 12533 14711 14771 14646 14452>,
			<12845 12632 14724 14935 14995 15587>,
			<12908 12789 14922 16076 15985 16152>,
			<12859 12905 15466 16151 15845 15484>,
			<12820 12861 15292 15394 15245 16631>,
			<12603 12690 15637 16797 15173 16758>,
			<11820 12689 16455 18951 17406 17291>,
			<10639 12058 17252 20960 21707 21533>,
			<10639 12058 17252 20960 21707 21533>,
			<10639 12058 17252 20960 21707 21533>;
	};

	qcom,pc-temp-y6-lut {
		qcom,lut-col-legend = <(-10) 0 10 25 40 50>;
		qcom,lut-row-legend = <10000 9800 9600 9400 9200 9000>,
			<8800 8600 8400 8200 8000 7800>,
			<7600 7400 7200 7000 6800 6600>,
			<6400 6200 6000 5800 5600 5400>,
			<5200 5000 4800 4600 4400 4200>,
			<4000 3800 3600 3400 3200 3000>,
			<2800 2600 2400 2200 2000 1800>,
			<1600 1400 1200 1000 900 800>,
			<700 600 500 400 300 200>,
			<100 0>;
		qcom,lut-data = <6157 5492 5228 5112 5087 5082>,
			<6170 5499 5231 5113 5088 5081>,
			<6186 5508 5235 5114 5089 5081>,
			<6203 5519 5238 5116 5090 5082>,
			<6218 5527 5240 5117 5092 5083>,
			<6226 5532 5242 5119 5094 5084>,
			<6229 5533 5243 5121 5096 5086>,
			<6231 5533 5245 5123 5098 5088>,
			<6225 5534 5247 5126 5100 5090>,
			<6191 5536 5253 5129 5103 5092>,
			<6169 5539 5257 5133 5105 5094>,
			<6251 5560 5258 5136 5108 5097>,
			<6386 5588 5258 5139 5111 5099>,
			<6375 5591 5266 5144 5115 5102>,
			<6151 5575 5294 5154 5120 5106>,
			<5995 5552 5310 5161 5126 5110>,
			<6003 5503 5297 5166 5132 5113>,
			<6018 5451 5277 5169 5138 5117>,
			<6024 5447 5267 5170 5141 5121>,
			<6023 5467 5261 5169 5142 5126>,
			<6021 5479 5253 5164 5140 5127>,
			<6020 5472 5236 5141 5120 5111>,
			<6018 5461 5219 5116 5095 5088>,
			<6021 5452 5216 5113 5091 5083>,
			<6030 5444 5215 5113 5090 5083>,
			<6042 5440 5214 5113 5090 5083>,
			<6056 5440 5215 5115 5092 5085>,
			<6074 5440 5216 5119 5096 5088>,
			<6093 5441 5217 5122 5100 5091>,
			<6115 5442 5219 5125 5105 5095>,
			<6143 5445 5220 5129 5109 5099>,
			<6180 5451 5220 5133 5113 5104>,
			<6227 5461 5219 5136 5116 5108>,
			<6282 5472 5220 5138 5116 5108>,
			<6351 5487 5223 5139 5115 5106>,
			<6424 5506 5226 5139 5112 5101>,
			<6496 5532 5232 5133 5105 5094>,
			<6568 5565 5239 5125 5096 5087>,
			<6625 5605 5244 5125 5096 5087>,
			<6672 5654 5247 5125 5098 5088>,
			<6710 5705 5251 5125 5099 5090>,
			<6742 5754 5258 5125 5099 5090>,
			<6772 5806 5263 5125 5099 5090>,
			<6808 5867 5266 5119 5093 5084>,
			<6850 5938 5274 5117 5093 5084>,
			<6808 5893 5272 5125 5101 5093>,
			<6779 5932 5281 5133 5108 5099>,
			<6790 6000 5301 5142 5117 5111>,
			<6866 6069 5324 5156 5130 5123>,
			<6942 6148 5341 5155 5124 5111>,
			<7022 6248 5333 5133 5104 5096>,
			<7133 6432 5363 5137 5105 5097>,
			<7562 6660 5428 5151 5113 5102>,
			<8693 7082 5530 5184 5135 5119>,
			<8693 7082 5530 5184 5135 5119>,
			<8693 7082 5530 5184 5135 5119>;
	};

};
